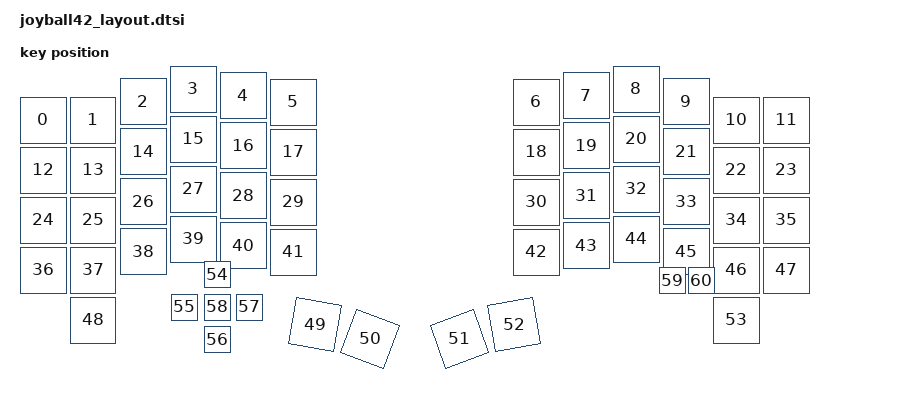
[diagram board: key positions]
// Generated by hardware/gen/generate.py. Used by ZMK Studio to draw the keyboard.
#include <physical_layouts.dtsi>

/ {
    joyball42_layout: joyball42_layout {
        compatible = "zmk,physical-layout";
        display-name = "Joyball42";
        transform = <&default_transform>;
        keys
            = <&key_physical_attrs 100 100 5 67 0 55 117>
            , <&key_physical_attrs 100 100 105 67 0 155 117>
            , <&key_physical_attrs 100 100 205 30 0 255 80>
            , <&key_physical_attrs 100 100 305 5 0 355 55>
            , <&key_physical_attrs 100 100 405 18 0 455 68>
            , <&key_physical_attrs 100 100 505 31 0 555 81>
            , <&key_physical_attrs 100 100 991 31 0 1041 81>
            , <&key_physical_attrs 100 100 1091 18 0 1141 68>
            , <&key_physical_attrs 100 100 1191 5 0 1241 55>
            , <&key_physical_attrs 100 100 1291 30 0 1341 80>
            , <&key_physical_attrs 100 100 1391 67 0 1441 117>
            , <&key_physical_attrs 100 100 1491 67 0 1541 117>
            , <&key_physical_attrs 100 100 5 167 0 55 217>
            , <&key_physical_attrs 100 100 105 167 0 155 217>
            , <&key_physical_attrs 100 100 205 130 0 255 180>
            , <&key_physical_attrs 100 100 305 105 0 355 155>
            , <&key_physical_attrs 100 100 405 118 0 455 168>
            , <&key_physical_attrs 100 100 505 131 0 555 181>
            , <&key_physical_attrs 100 100 991 131 0 1041 181>
            , <&key_physical_attrs 100 100 1091 118 0 1141 168>
            , <&key_physical_attrs 100 100 1191 105 0 1241 155>
            , <&key_physical_attrs 100 100 1291 130 0 1341 180>
            , <&key_physical_attrs 100 100 1391 167 0 1441 217>
            , <&key_physical_attrs 100 100 1491 167 0 1541 217>
            , <&key_physical_attrs 100 100 5 267 0 55 317>
            , <&key_physical_attrs 100 100 105 267 0 155 317>
            , <&key_physical_attrs 100 100 205 230 0 255 280>
            , <&key_physical_attrs 100 100 305 205 0 355 255>
            , <&key_physical_attrs 100 100 405 218 0 455 268>
            , <&key_physical_attrs 100 100 505 231 0 555 281>
            , <&key_physical_attrs 100 100 991 231 0 1041 281>
            , <&key_physical_attrs 100 100 1091 218 0 1141 268>
            , <&key_physical_attrs 100 100 1191 205 0 1241 255>
            , <&key_physical_attrs 100 100 1291 230 0 1341 280>
            , <&key_physical_attrs 100 100 1391 267 0 1441 317>
            , <&key_physical_attrs 100 100 1491 267 0 1541 317>
            , <&key_physical_attrs 100 100 5 367 0 55 417>
            , <&key_physical_attrs 100 100 105 367 0 155 417>
            , <&key_physical_attrs 100 100 205 330 0 255 380>
            , <&key_physical_attrs 100 100 305 305 0 355 355>
            , <&key_physical_attrs 100 100 405 318 0 455 368>
            , <&key_physical_attrs 100 100 505 331 0 555 381>
            , <&key_physical_attrs 100 100 991 331 0 1041 381>
            , <&key_physical_attrs 100 100 1091 318 0 1141 368>
            , <&key_physical_attrs 100 100 1191 305 0 1241 355>
            , <&key_physical_attrs 100 100 1291 330 0 1341 380>
            , <&key_physical_attrs 100 100 1391 367 0 1441 417>
            , <&key_physical_attrs 100 100 1491 367 0 1541 417>
            , <&key_physical_attrs 100 100 105 467 0 155 517>
            , <&key_physical_attrs 100 100 549 476 (1000) 599 526>
            , <&key_physical_attrs 100 100 659 505 (2000) 709 555>
            , <&key_physical_attrs 100 100 838 505 (-2000) 888 555>
            , <&key_physical_attrs 100 100 947 476 (-1000) 997 526>
            , <&key_physical_attrs 100 100 1391 467 0 1441 517>
            , <&key_physical_attrs 60 60 373 396 0 403 426>
            , <&key_physical_attrs 60 60 308 461 0 338 491>
            , <&key_physical_attrs 60 60 373 526 0 403 556>
            , <&key_physical_attrs 60 60 438 461 0 468 491>
            , <&key_physical_attrs 60 60 373 461 0 403 491>
            , <&key_physical_attrs 60 60 1284 408 0 1314 438>
            , <&key_physical_attrs 60 60 1342 408 0 1372 438>
            ;
    };
};
